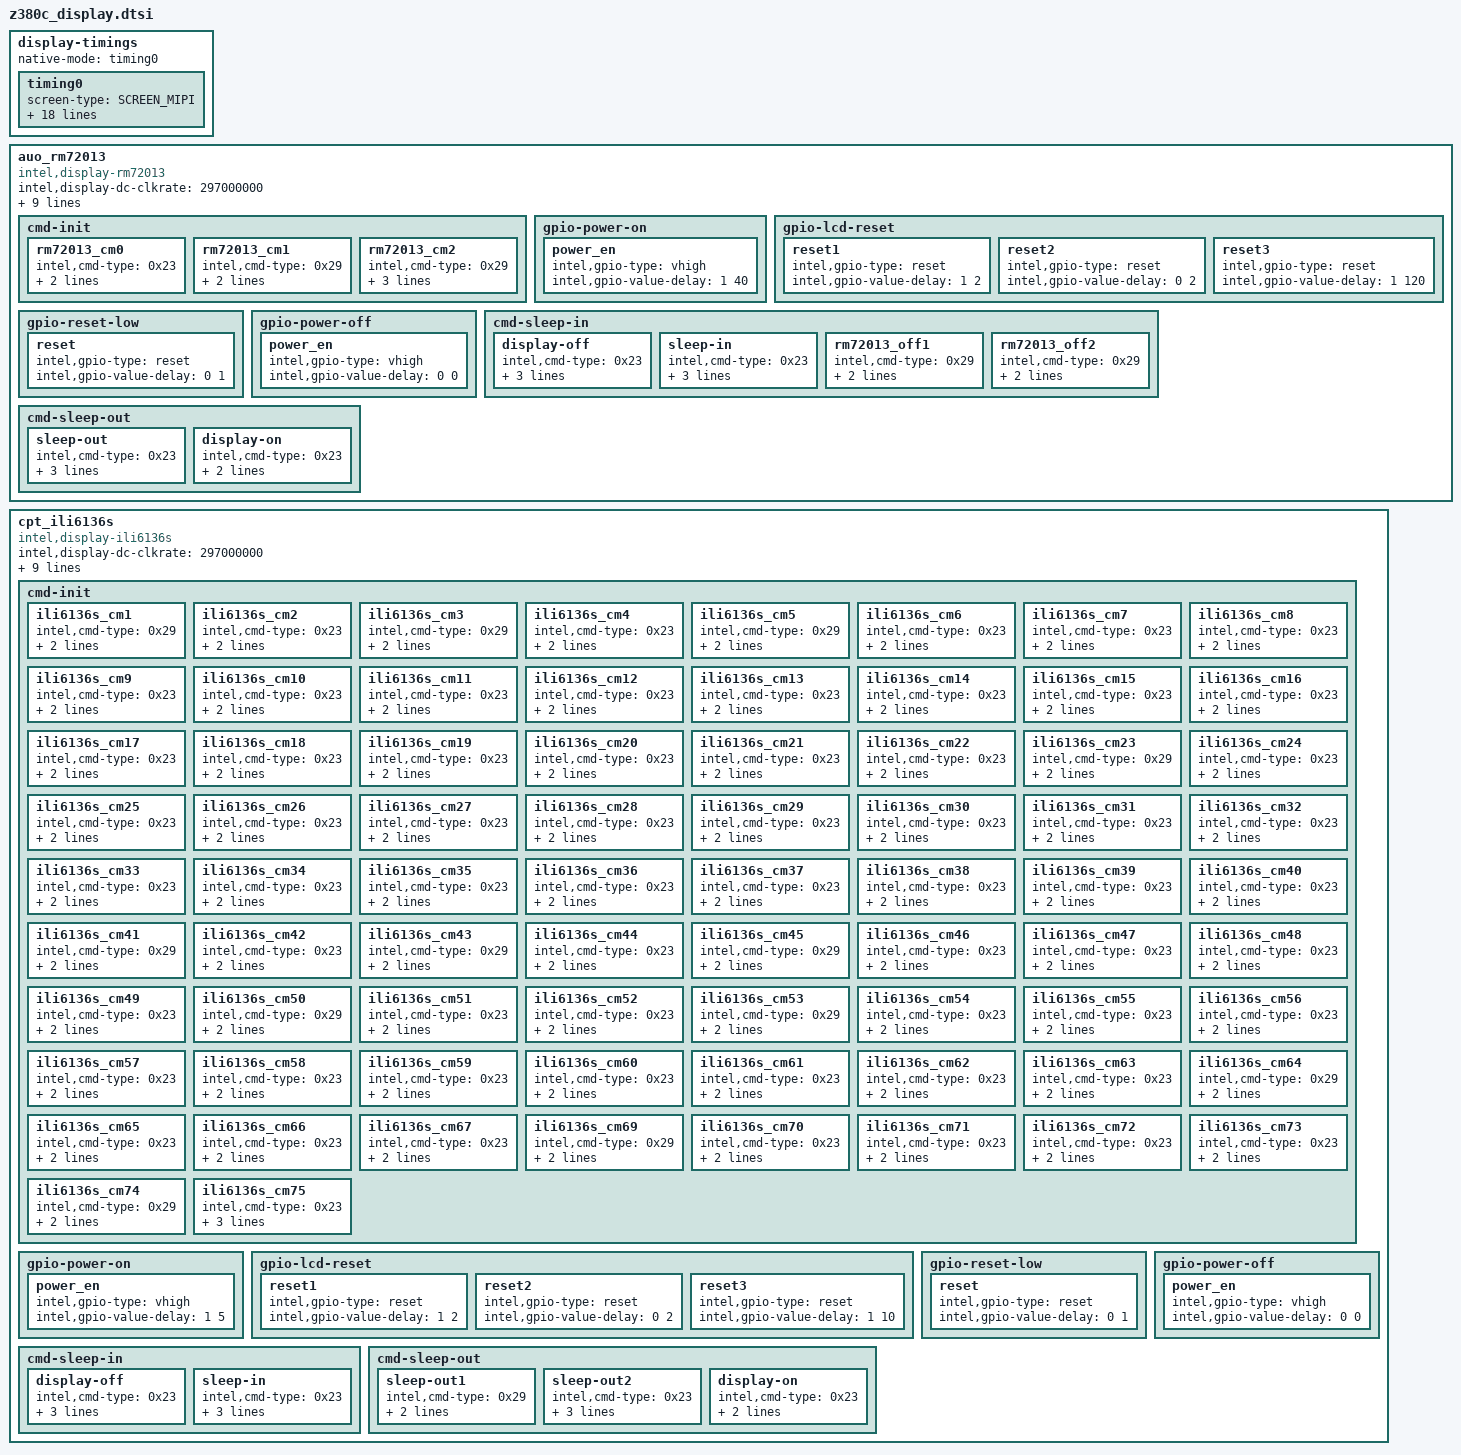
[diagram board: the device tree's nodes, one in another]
/*
 * definition at "include/dt-bindings/sofiafb/sofia_fb.h"
 */

display-timings {
	native-mode = <&timing0>;
	timing0: timing0 {
		screen-type = <SCREEN_MIPI>;
		out-face    = <OUT_P888>;
		color-mode = <COLOR_RGB>;
		clock-frequency = <69641520>;
		hactive = <800>;
		vactive = <1280>;
		hback-porch = <40>;
		hfront-porch = <40>;
		vback-porch = <15>;
		vfront-porch = <15>;
		hsync-len = <4>;
		vsync-len = <3>;
		hsync-active = <0>;
		vsync-active = <0>;
		de-active = <0>;
		pixelclk-active = <0>;
		swap-rb = <0>;
		swap-rg = <0>;
		swap-gb = <0>;
	};
};

auo_rm72013 {
	compatible = "intel,display-rm72013";
	intel,display-dc-clkrate = <297000000>;
	intel,display-preinit = <0>;
	intel,display-ramless = <1>;
	intel,display-fps = <60>;
	intel,display-dsi-datarate = <421000000>;
	intel,display-vid-mode = "pulses";
	intel,display-vid-id = <0>;
	intel,display-if-nblanes = <4>;
	intel,display-eot = <0>;
	intel,display-gate = <0>;

	cmd-init {
		rm72013_cm0 {
			intel,cmd-type = <0x23>;
			intel,cmd-data = <0x35 0x00>;
			intel,cmd-lp = <1>;
		};
		rm72013_cm1 {
			intel,cmd-type = <0x29>;
			intel,cmd-data = <0xF0 0x5A 0x5A>;
			intel,cmd-lp = <1>;
		};
		rm72013_cm2 {
			intel,cmd-type = <0x29>;
			intel,cmd-data = <0xC3 0x40 0x00 0x28>;
			intel,cmd-delay = <6>;
			intel,cmd-lp = <1>;
		};
	};

	gpio-power-on {
		power_en {
			intel,gpio-type = "vhigh";
			intel,gpio-value-delay = <1 40>;
		};
	};

	gpio-lcd-reset {
		reset1 {
			intel,gpio-type = "reset";
			intel,gpio-value-delay = <1 2>;
		};
		reset2 {
			intel,gpio-type = "reset";
			intel,gpio-value-delay = <0 2>;
		};
		reset3 {
			intel,gpio-type = "reset";
			intel,gpio-value-delay = <1 120>;
		};
	};

	gpio-reset-low {
		reset {
			intel,gpio-type = "reset";
			intel,gpio-value-delay = <0 1>;
		};
	};

	gpio-power-off {
		power_en {
			intel,gpio-type = "vhigh";
			intel,gpio-value-delay = <0 0>;
		};
	};

	cmd-sleep-in {
		display-off {
			intel,cmd-type = <0x23>;
			intel,cmd-data = <0x28 0x00>;
			intel,cmd-delay = <20>;
			intel,cmd-lp = <1>;
		};
		sleep-in {
			intel,cmd-type = <0x23>;
			intel,cmd-data = <0x10 0x00>;
			intel,cmd-delay = <5>;
			intel,cmd-lp = <1>;
		};
		rm72013_off1 {
			intel,cmd-type = <0x29>;
			intel,cmd-data = <0xF0 0x5A 0x5A>;
			intel,cmd-lp = <1>;
		};
		rm72013_off2 {
			intel,cmd-type = <0x29>;
			intel,cmd-data = <0xC3 0x40 0x00 0x20>;
			intel,cmd-lp = <1>;
		};
	};

	cmd-sleep-out {
		sleep-out {
			intel,cmd-type = <0x23>;
			intel,cmd-data = <0x11 0x00>;
			intel,cmd-delay = <120>;
			intel,cmd-lp = <1>;
		};
		display-on {
			intel,cmd-type = <0x23>;
			intel,cmd-data = <0x29 0x00>;
			intel,cmd-lp = <1>;
		};
	};
};

cpt_ili6136s {
	compatible = "intel,display-ili6136s";
	intel,display-dc-clkrate = <297000000>;
	intel,display-preinit = <0>;
	intel,display-ramless = <1>;
	intel,display-fps = <60>;
	intel,display-dsi-datarate = <421000000>;
	intel,display-vid-mode = "pulses";
	intel,display-vid-id = <0>;
	intel,display-if-nblanes = <4>;
	intel,display-eot = <0>;
	intel,display-gate = <0>;

	cmd-init {
		ili6136s_cm1 {
			intel,cmd-type = <0x29>;
			intel,cmd-data = <0xFF 0x61 0x36 0x08>;
			intel,cmd-lp = <1>;
		};
		ili6136s_cm2 {
			intel,cmd-type = <0x23>;
			intel,cmd-data = <0x1C 0xA0>;
			intel,cmd-lp = <1>;
		};
		ili6136s_cm3 {
			intel,cmd-type = <0x29>;
			intel,cmd-data = <0xFF 0x61 0x36 0x08>;
			intel,cmd-lp = <1>;
		};
		ili6136s_cm4 {
			intel,cmd-type = <0x23>;
			intel,cmd-data = <0x4C 0x00>;
			intel,cmd-lp = <1>;
		};
		ili6136s_cm5 {
			intel,cmd-type = <0x29>;
			intel,cmd-data = <0xFF 0x61 0x36 0x01>;
			intel,cmd-lp = <1>;
		};
		ili6136s_cm6 {
			intel,cmd-type = <0x23>;
			intel,cmd-data = <0xA0 0x05>;
			intel,cmd-lp = <1>;
		};
		ili6136s_cm7 {
			intel,cmd-type = <0x23>;
			intel,cmd-data = <0xA1 0x05>;
			intel,cmd-lp = <1>;
		};
		ili6136s_cm8 {
			intel,cmd-type = <0x23>;
			intel,cmd-data = <0xA2 0x06>;
			intel,cmd-lp = <1>;
		};
		ili6136s_cm9 {
			intel,cmd-type = <0x23>;
			intel,cmd-data = <0xA3 0x0d>;
			intel,cmd-lp = <1>;
		};
		ili6136s_cm10 {
			intel,cmd-type = <0x23>;
			intel,cmd-data = <0xA4 0x04>;
			intel,cmd-lp = <1>;
		};
		ili6136s_cm11 {
			intel,cmd-type = <0x23>;
			intel,cmd-data = <0xA5 0x07>;
			intel,cmd-lp = <1>;
		};
		ili6136s_cm12 {
			intel,cmd-type = <0x23>;
			intel,cmd-data = <0xA6 0x0f>;
			intel,cmd-lp = <1>;
		};
		ili6136s_cm13 {
			intel,cmd-type = <0x23>;
			intel,cmd-data = <0xA7 0x14>;
			intel,cmd-lp = <1>;
		};
		ili6136s_cm14 {
			intel,cmd-type = <0x23>;
			intel,cmd-data = <0xA8 0x1F>;
			intel,cmd-lp = <1>;
		};
		ili6136s_cm15 {
			intel,cmd-type = <0x23>;
			intel,cmd-data = <0xA9 0x28>;
			intel,cmd-lp = <1>;
		};
		ili6136s_cm16 {
			intel,cmd-type = <0x23>;
			intel,cmd-data = <0xAA 0x31>;
			intel,cmd-lp = <1>;
		};
		ili6136s_cm17 {
			intel,cmd-type = <0x23>;
			intel,cmd-data = <0xAB 0x39>;
			intel,cmd-lp = <1>;
		};
		ili6136s_cm18 {
			intel,cmd-type = <0x23>;
			intel,cmd-data = <0xAC 0x39>;
			intel,cmd-lp = <1>;
		};
		ili6136s_cm19 {
			intel,cmd-type = <0x23>;
			intel,cmd-data = <0xAD 0x31>;
			intel,cmd-lp = <1>;
		};
		ili6136s_cm20 {
			intel,cmd-type = <0x23>;
			intel,cmd-data = <0xAE 0x2e>;
			intel,cmd-lp = <1>;
		};
		ili6136s_cm21 {
			intel,cmd-type = <0x23>;
			intel,cmd-data = <0xAF 0x2f>;
			intel,cmd-lp = <1>;
		};
		ili6136s_cm22 {
			intel,cmd-type = <0x23>;
			intel,cmd-data = <0xB0 0x3c>;
			intel,cmd-lp = <1>;
		};
		ili6136s_cm23 {
			intel,cmd-type = <0x29>;
			intel,cmd-data = <0xFF 0x61 0x36 0x01>;
			intel,cmd-lp = <1>;
		};
		ili6136s_cm24 {
			intel,cmd-type = <0x23>;
			intel,cmd-data = <0xC0 0x05>;
			intel,cmd-lp = <1>;
		};
		ili6136s_cm25 {
			intel,cmd-type = <0x23>;
			intel,cmd-data = <0xC1 0x05>;
			intel,cmd-lp = <1>;
		};
		ili6136s_cm26 {
			intel,cmd-type = <0x23>;
			intel,cmd-data = <0xC2 0x06>;
			intel,cmd-lp = <1>;
		};
		ili6136s_cm27 {
			intel,cmd-type = <0x23>;
			intel,cmd-data = <0xC3 0x0d>;
			intel,cmd-lp = <1>;
		};
		ili6136s_cm28 {
			intel,cmd-type = <0x23>;
			intel,cmd-data = <0xC4 0x04>;
			intel,cmd-lp = <1>;
		};
		ili6136s_cm29 {
			intel,cmd-type = <0x23>;
			intel,cmd-data = <0xC5 0x07>;
			intel,cmd-lp = <1>;
		};
		ili6136s_cm30 {
			intel,cmd-type = <0x23>;
			intel,cmd-data = <0xC6 0x0f>;
			intel,cmd-lp = <1>;
		};
		ili6136s_cm31 {
			intel,cmd-type = <0x23>;
			intel,cmd-data = <0xC7 0x14>;
			intel,cmd-lp = <1>;
		};
		ili6136s_cm32 {
			intel,cmd-type = <0x23>;
			intel,cmd-data = <0xC8 0x1F>;
			intel,cmd-lp = <1>;
		};
		ili6136s_cm33 {
			intel,cmd-type = <0x23>;
			intel,cmd-data = <0xC9 0x28>;
			intel,cmd-lp = <1>;
		};
		ili6136s_cm34 {
			intel,cmd-type = <0x23>;
			intel,cmd-data = <0xCA 0x31>;
			intel,cmd-lp = <1>;
		};
		ili6136s_cm35 {
			intel,cmd-type = <0x23>;
			intel,cmd-data = <0xCB 0x39>;
			intel,cmd-lp = <1>;
		};
		ili6136s_cm36 {
			intel,cmd-type = <0x23>;
			intel,cmd-data = <0xCC 0x39>;
			intel,cmd-lp = <1>;
		};
		ili6136s_cm37 {
			intel,cmd-type = <0x23>;
			intel,cmd-data = <0xCD 0x31>;
			intel,cmd-lp = <1>;
		};
		ili6136s_cm38 {
			intel,cmd-type = <0x23>;
			intel,cmd-data = <0xCE 0x2e>;
			intel,cmd-lp = <1>;
		};
		ili6136s_cm39 {
			intel,cmd-type = <0x23>;
			intel,cmd-data = <0xCF 0x2f>;
			intel,cmd-lp = <1>;
		};
		ili6136s_cm40 {
			intel,cmd-type = <0x23>;
			intel,cmd-data = <0xD0 0x3c>;
			intel,cmd-lp = <1>;
		};
		ili6136s_cm41 {
			intel,cmd-type = <0x29>;
			intel,cmd-data = <0xFF 0x61 0x36 0x08>;
			intel,cmd-lp = <1>;
		};
		ili6136s_cm42 {
			intel,cmd-type = <0x23>;
			intel,cmd-data = <0xE9 0x0B>;
			intel,cmd-lp = <1>;
		};
		ili6136s_cm43 {
			intel,cmd-type = <0x29>;
			intel,cmd-data = <0xFF 0x61 0x36 0x06>;
			intel,cmd-lp = <1>;
		};
		ili6136s_cm44 {
			intel,cmd-type = <0x23>;
			intel,cmd-data = <0x72 0x01>;
			intel,cmd-lp = <1>;
		};
		ili6136s_cm45 {
			intel,cmd-type = <0x29>;
			intel,cmd-data = <0xFF 0x61 0x36 0x08>;
			intel,cmd-lp = <1>;
		};
		ili6136s_cm46 {
			intel,cmd-type = <0x23>;
			intel,cmd-data = <0x93 0x08>;
			intel,cmd-lp = <1>;
		};
		ili6136s_cm47 {
			intel,cmd-type = <0x23>;
			intel,cmd-data = <0x8E 0x12>;
			intel,cmd-lp = <1>;
		};
		ili6136s_cm48 {
			intel,cmd-type = <0x23>;
			intel,cmd-data = <0x76 0xB4>;
			intel,cmd-lp = <1>;
		};
		ili6136s_cm49 {
			intel,cmd-type = <0x23>;
			intel,cmd-data = <0x78 0x02>;
			intel,cmd-lp = <1>;
		};
		ili6136s_cm50 {
			intel,cmd-type = <0x29>;
			intel,cmd-data = <0xFF 0x61 0x36 0x01>;
			intel,cmd-lp = <1>;
		};
		ili6136s_cm51 {
			intel,cmd-type = <0x23>;
			intel,cmd-data = <0x42 0x43>;
			intel,cmd-lp = <1>;
		};
		ili6136s_cm52 {
			intel,cmd-type = <0x23>;
			intel,cmd-data = <0x60 0x14>;
			intel,cmd-lp = <1>;
		};
		ili6136s_cm53 {
			intel,cmd-type = <0x29>;
			intel,cmd-data = <0xFF 0x61 0x36 0x07>;
			intel,cmd-lp = <1>;
		};
		ili6136s_cm54 {
			intel,cmd-type = <0x23>;
			intel,cmd-data = <0x1A 0x05>;
			intel,cmd-lp = <1>;
		};
		ili6136s_cm55 {
			intel,cmd-type = <0x23>;
			intel,cmd-data = <0x16 0x1F>;
			intel,cmd-lp = <1>;
		};
		ili6136s_cm56 {
			intel,cmd-type = <0x23>;
			intel,cmd-data = <0x17 0x1F>;
			intel,cmd-lp = <1>;
		};
		ili6136s_cm57 {
			intel,cmd-type = <0x23>;
			intel,cmd-data = <0x18 0x05>;
			intel,cmd-lp = <1>;
		};
		ili6136s_cm58 {
			intel,cmd-type = <0x23>;
			intel,cmd-data = <0x19 0x00>;
			intel,cmd-lp = <1>;
		};
		ili6136s_cm59 {
			intel,cmd-type = <0x23>;
			intel,cmd-data = <0x0D 0x05>;
			intel,cmd-lp = <1>;
		};
		ili6136s_cm60 {
			intel,cmd-type = <0x23>;
			intel,cmd-data = <0x0A 0x03>;
			intel,cmd-lp = <1>;
		};
		ili6136s_cm61 {
			intel,cmd-type = <0x23>;
			intel,cmd-data = <0x0E 0x35>;
			intel,cmd-lp = <1>;
		};
		ili6136s_cm62 {
			intel,cmd-type = <0x23>;
			intel,cmd-data = <0x0B 0x1F>;
			intel,cmd-lp = <1>;
		};
		ili6136s_cm63 {
			intel,cmd-type = <0x23>;
			intel,cmd-data = <0x1C 0xEB>;
			intel,cmd-lp = <1>;
		};
		ili6136s_cm64 {
			intel,cmd-type = <0x29>;
			intel,cmd-data = <0xFF 0x61 0x36 0x08>;
			intel,cmd-lp = <1>;
		};
		ili6136s_cm65 {
			intel,cmd-type = <0x23>;
			intel,cmd-data = <0x6C 0x02>;
			intel,cmd-lp = <1>;
		};
		ili6136s_cm66 {
			intel,cmd-type = <0x23>;
			intel,cmd-data = <0x5F 0x0F>;
			intel,cmd-lp = <1>;
		};
		ili6136s_cm67 {
			intel,cmd-type = <0x23>;
			intel,cmd-data = <0xAB 0x24>;
			intel,cmd-lp = <1>;
		};
#if 0
		ili6136s_cm68 {
			intel,cmd-type = <0x23>;
			intel,cmd-data = <0x95 0x49>;
			intel,cmd-lp = <1>;
		};
#endif
		ili6136s_cm69 {
			intel,cmd-type = <0x29>;
			intel,cmd-data = <0xFF 0x61 0x36 0x01>;
			intel,cmd-lp = <1>;
		};
		ili6136s_cm70 {
			intel,cmd-type = <0x23>;
			intel,cmd-data = <0x38 0x00>;
			intel,cmd-lp = <1>;
		};
		ili6136s_cm71 {
			intel,cmd-type = <0x23>;
			intel,cmd-data = <0x39 0x1F>;
			intel,cmd-lp = <1>;
		};
		ili6136s_cm72 {
			intel,cmd-type = <0x23>;
			intel,cmd-data = <0x50 0x85>;
			intel,cmd-lp = <1>;
		};
		ili6136s_cm73 {
			intel,cmd-type = <0x23>;
			intel,cmd-data = <0x51 0x85>;
			intel,cmd-lp = <1>;
		};
		ili6136s_cm74 {
			intel,cmd-type = <0x29>;
			intel,cmd-data = <0xFF 0x61 0x36 0x00>;
			intel,cmd-lp = <1>;
		};
		ili6136s_cm75 {
			intel,cmd-type = <0x23>;
			intel,cmd-data = <0x35 0x01>;
			intel,cmd-delay = <20>;
			intel,cmd-lp = <1>;
		};
	};

	gpio-power-on {
		power_en {
			intel,gpio-type = "vhigh";
			intel,gpio-value-delay = <1 5>;
		};
	};

	gpio-lcd-reset {
		reset1 {
			intel,gpio-type = "reset";
			intel,gpio-value-delay = <1 2>;
		};
		reset2 {
			intel,gpio-type = "reset";
			intel,gpio-value-delay = <0 2>;
		};
		reset3 {
			intel,gpio-type = "reset";
			intel,gpio-value-delay = <1 10>;
		};
	};

	gpio-reset-low {
		reset {
			intel,gpio-type = "reset";
			intel,gpio-value-delay = <0 1>;
		};
	};

	gpio-power-off {
		power_en {
			intel,gpio-type = "vhigh";
			intel,gpio-value-delay = <0 0>;
		};
	};

	cmd-sleep-in {
		display-off {
			intel,cmd-type = <0x23>;
			intel,cmd-data = <0x28 0x00>;
			intel,cmd-delay = <20>;
			intel,cmd-lp = <1>;
		};
		sleep-in {
			intel,cmd-type = <0x23>;
			intel,cmd-data = <0x10 0x00>;
			intel,cmd-delay = <180>;
			intel,cmd-lp = <1>;
		};
	};

	cmd-sleep-out {
		sleep-out1 {
			intel,cmd-type = <0x29>;
			intel,cmd-data = <0xFF 0x61 0x36 0x00>;
			intel,cmd-lp = <1>;
		};
		sleep-out2 {
			intel,cmd-type = <0x23>;
			intel,cmd-data = <0x11 0x00>;
			intel,cmd-delay = <150>;
			intel,cmd-lp = <1>;
		};
		display-on {
			intel,cmd-type = <0x23>;
			intel,cmd-data = <0x29 0x00>;
			intel,cmd-lp = <1>;
		};
	};
};
